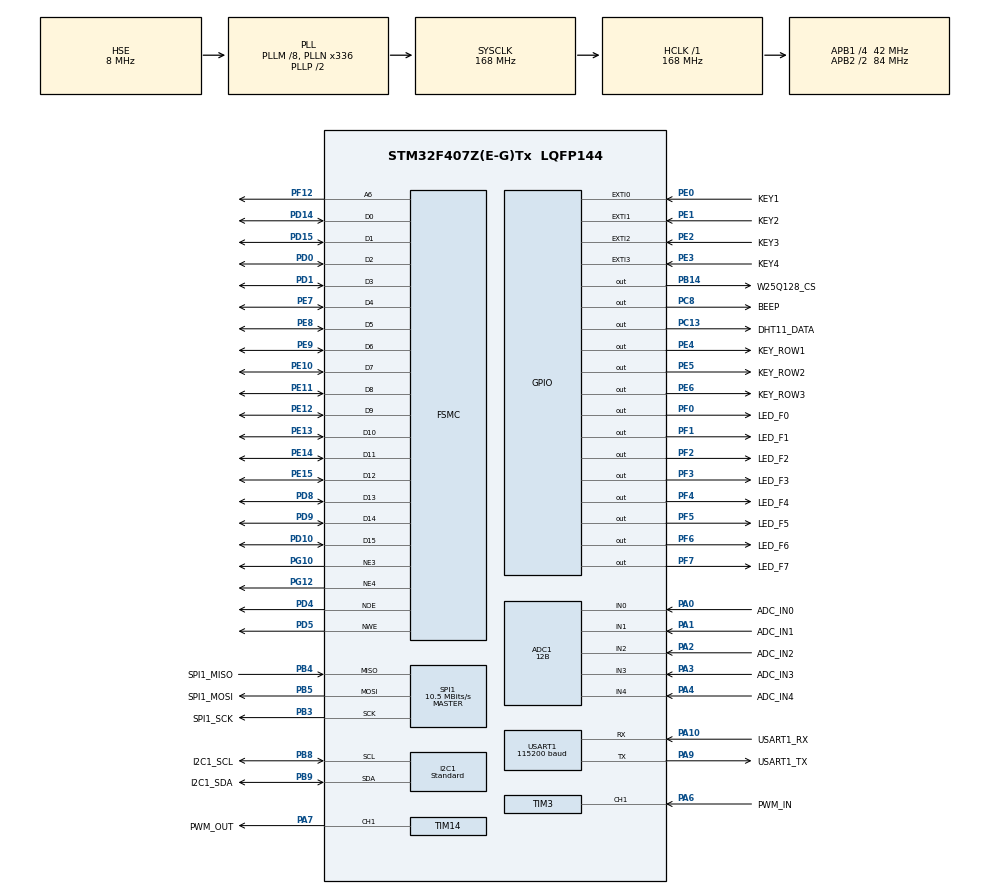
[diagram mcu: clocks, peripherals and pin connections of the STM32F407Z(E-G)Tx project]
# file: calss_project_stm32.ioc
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ADC1.Channel-0\#ChannelRegularConversion=ADC_CHANNEL_0
ADC1.Channel-1\#ChannelRegularConversion=ADC_CHANNEL_1
ADC1.Channel-2\#ChannelRegularConversion=ADC_CHANNEL_2
ADC1.Channel-3\#ChannelRegularConversion=ADC_CHANNEL_3
ADC1.Channel-4\#ChannelRegularConversion=ADC_CHANNEL_4
ADC1.ContinuousConvMode=ENABLE
ADC1.DMAContinuousRequests=ENABLE
ADC1.DataAlign=ADC_DATAALIGN_RIGHT
ADC1.DiscontinuousConvMode=DISABLE
ADC1.EOCSelection=ADC_EOC_SINGLE_CONV
ADC1.ExternalTrigConv=ADC_SOFTWARE_START
ADC1.ExternalTrigConvEdge=ADC_EXTERNALTRIGCONVEDGE_NONE
ADC1.NbrOfConversion=5
ADC1.NbrOfConversionFlag=1
ADC1.Overrun=ADC_OVR_DATA_PRESERVED
ADC1.Rank-0\#ChannelRegularConversion=1
ADC1.Rank-1\#ChannelRegularConversion=2
ADC1.Rank-2\#ChannelRegularConversion=3
ADC1.Rank-3\#ChannelRegularConversion=4
ADC1.Rank-4\#ChannelRegularConversion=5
ADC1.Resolution=ADC_RESOLUTION_12B
ADC1.SamplingTime-0\#ChannelRegularConversion=ADC_SAMPLETIME_84CYCLES
ADC1.SamplingTime-1\#ChannelRegularConversion=ADC_SAMPLETIME_84CYCLES
ADC1.SamplingTime-2\#ChannelRegularConversion=ADC_SAMPLETIME_84CYCLES
ADC1.SamplingTime-3\#ChannelRegularConversion=ADC_SAMPLETIME_84CYCLES
ADC1.SamplingTime-4\#ChannelRegularConversion=ADC_SAMPLETIME_84CYCLES
ADC1.ScanConvMode=ENABLE
ADC1.master=1
Dma.ADC1.0.Direction=DMA_PERIPH_TO_MEMORY
Dma.ADC1.0.FIFOMode=DMA_FIFOMODE_DISABLE
Dma.ADC1.0.Instance=DMA2_Stream0
Dma.ADC1.0.MemDataAlignment=DMA_MDATAALIGN_HALFWORD
Dma.ADC1.0.MemInc=DMA_MINC_ENABLE
Dma.ADC1.0.Mode=DMA_CIRCULAR
Dma.ADC1.0.PeriphDataAlignment=DMA_PDATAALIGN_HALFWORD
Dma.ADC1.0.PeriphInc=DMA_PINC_DISABLE
Dma.ADC1.0.Priority=DMA_PRIORITY_MEDIUM
Dma.Request0=ADC1
FREERTOS.Tasks01=myTask_key,24,128,StartTask_key,Default,NULL,Dynamic,NULL,NULL;myTask_control,16,256,StartTask_control,Default,NULL,Dynamic,NULL,NULL;myTask_shell,24,512,StartTask_shell,Default,NULL,Dynamic,NULL,NULL;myTask_timer,24,256,StartTask_timer,Default,NULL,Dynamic,NULL,NULL;myTask_seg,16,128,StartTask_seg,Default,NULL,Dynamic,NULL,NULL;myTask_lcd,16,512,StartTask_lcd,Default,NULL,Dynamic,NULL,NULL
I2C1.I2C_Speed_Mode=I2C_Standard
I2C1.Speed=100
Mcu.Family=STM32F4
Mcu.Name=STM32F407Z(E-G)Tx
Mcu.Package=LQFP144
NVIC.DMA2_Stream0_IRQn=true\:5\:0\:false\:false\:true\:true\:true\:true\:true
NVIC.EXTI0_IRQn=true\:5\:0\:false\:false\:true\:true\:true\:true\:true
NVIC.EXTI1_IRQn=true\:5\:0\:false\:false\:true\:true\:true\:true\:true
NVIC.EXTI2_IRQn=true\:5\:0\:false\:false\:true\:true\:true\:true\:true
NVIC.EXTI3_IRQn=true\:5\:0\:false\:false\:true\:true\:true\:true\:true
NVIC.PriorityGroup=NVIC_PRIORITYGROUP_4
NVIC.TIM1_UP_TIM10_IRQn=true\:15\:0\:false\:false\:true\:false\:false\:true\:true
NVIC.TIM3_IRQn=true\:5\:0\:false\:false\:true\:true\:true\:true\:true
NVIC.TIM6_DAC_IRQn=true\:5\:0\:false\:false\:true\:true\:true\:true\:true
NVIC.TimeBase=TIM1_UP_TIM10_IRQn
NVIC.TimeBaseIP=TIM1
NVIC.USART1_IRQn=true\:5\:0\:false\:false\:true\:true\:true\:true\:true
PA0-WKUP.GPIO_Label=ADC_IN0
PA0-WKUP.Signal=ADCx_IN0
PA1.GPIO_Label=ADC_IN1
PA1.Signal=ADCx_IN1
PA10.GPIO_Label=USART1_RX
PA10.GPIO_Mode=GPIO_MODE_AF_PP
PA10.GPIO_PuPd=GPIO_NOPULL
PA10.GPIO_Speed=GPIO_SPEED_FREQ_VERY_HIGH
PA10.Mode=Asynchronous
PA10.Signal=USART1_RX
PA13.Mode=Serial_Wire
PA13.Signal=SYS_JTMS-SWDIO
PA14.Mode=Serial_Wire
PA14.Signal=SYS_JTCK-SWCLK
PA2.GPIO_Label=ADC_IN2
PA2.Signal=ADCx_IN2
PA3.GPIO_Label=ADC_IN3
PA3.Signal=ADCx_IN3
PA4.GPIO_Label=ADC_IN4
PA4.Signal=ADCx_IN4
PA6.GPIO_Label=PWM_IN
PA6.Signal=S_TIM3_CH1
PA7.GPIO_Label=PWM_OUT
PA7.Signal=S_TIM14_CH1
PA9.GPIO_Label=USART1_TX
PA9.GPIO_Mode=GPIO_MODE_AF_PP
PA9.GPIO_PuPd=GPIO_NOPULL
PA9.GPIO_Speed=GPIO_SPEED_FREQ_VERY_HIGH
PA9.Mode=Asynchronous
PA9.Signal=USART1_TX
PB14.GPIO_Label=W25Q128_CS
PB14.GPIO_Speed=GPIO_SPEED_FREQ_HIGH
PB14.PinState=GPIO_PIN_SET
PB14.Signal=GPIO_Output
PB3.GPIO_Label=SPI1_SCK
PB3.GPIO_Mode=GPIO_MODE_AF_PP
PB3.GPIO_PuPd=GPIO_NOPULL
PB3.GPIO_Speed=GPIO_SPEED_FREQ_VERY_HIGH
PB3.Mode=Full_Duplex_Master
PB3.Signal=SPI1_SCK
PB4.GPIO_Label=SPI1_MISO
PB4.GPIO_Mode=GPIO_MODE_AF_PP
PB4.GPIO_PuPd=GPIO_NOPULL
PB4.GPIO_Speed=GPIO_SPEED_FREQ_VERY_HIGH
PB4.Mode=Full_Duplex_Master
PB4.Signal=SPI1_MISO
PB5.GPIO_Label=SPI1_MOSI
PB5.GPIO_Mode=GPIO_MODE_AF_PP
PB5.GPIO_PuPd=GPIO_NOPULL
PB5.GPIO_Speed=GPIO_SPEED_FREQ_VERY_HIGH
PB5.Mode=Full_Duplex_Master
PB5.Signal=SPI1_MOSI
PB8.GPIO_Label=I2C1_SCL
PB8.GPIO_Mode=GPIO_MODE_AF_OD
PB8.GPIO_PuPd=GPIO_NOPULL
PB8.GPIO_Speed=GPIO_SPEED_FREQ_LOW
PB8.Mode=I2C
PB8.Signal=I2C1_SCL
PB9.GPIO_Label=I2C1_SDA
PB9.GPIO_Mode=GPIO_MODE_AF_OD
PB9.GPIO_PuPd=GPIO_NOPULL
PB9.GPIO_Speed=GPIO_SPEED_FREQ_LOW
PB9.Mode=I2C
PB9.Signal=I2C1_SDA
PC13-ANTI_TAMP.GPIO_Label=DHT11_DATA
PC13-ANTI_TAMP.GPIO_ModeDefaultOutputPP=GPIO_MODE_OUTPUT_OD
PC13-ANTI_TAMP.GPIO_Speed=GPIO_SPEED_FREQ_LOW
PC13-ANTI_TAMP.PinState=GPIO_PIN_SET
PC13-ANTI_TAMP.Signal=GPIO_Output
PC8.GPIO_Label=BEEP
PC8.GPIO_Speed=GPIO_SPEED_FREQ_LOW
PC8.PinState=GPIO_PIN_SET
PC8.Signal=GPIO_Output
PD0.Signal=FSMC_D2_DA2
PD1.Signal=FSMC_D3_DA3
PD10.Signal=FSMC_D15_DA15
PD14.Signal=FSMC_D0_DA0
PD15.Signal=FSMC_D1_DA1
PD4.Signal=FSMC_NOE
PD5.Signal=FSMC_NWE
PD8.Signal=FSMC_D13_DA13
PD9.Signal=FSMC_D14_DA14
PE0.GPIO_Label=KEY1
PE0.GPIO_ModeDefaultEXTI=GPIO_MODE_IT_FALLING
PE0.GPIO_PuPd=GPIO_PULLUP
PE0.Signal=GPXTI0
PE1.GPIO_Label=KEY2
PE1.GPIO_ModeDefaultEXTI=GPIO_MODE_IT_FALLING
PE1.GPIO_PuPd=GPIO_PULLUP
PE1.Signal=GPXTI1
PE10.Signal=FSMC_D7_DA7
PE11.Signal=FSMC_D8_DA8
PE12.Signal=FSMC_D9_DA9
PE13.Signal=FSMC_D10_DA10
PE14.Signal=FSMC_D11_DA11
PE15.Signal=FSMC_D12_DA12
PE2.GPIO_Label=KEY3
PE2.GPIO_ModeDefaultEXTI=GPIO_MODE_IT_FALLING
PE2.GPIO_PuPd=GPIO_PULLUP
PE2.Signal=GPXTI2
PE3.GPIO_Label=KEY4
PE3.GPIO_ModeDefaultEXTI=GPIO_MODE_IT_FALLING
PE3.GPIO_PuPd=GPIO_PULLUP
PE3.Signal=GPXTI3
PE4.GPIO_Label=KEY_ROW1
PE4.GPIO_Speed=GPIO_SPEED_FREQ_LOW
PE4.PinState=GPIO_PIN_SET
PE4.Signal=GPIO_Output
PE5.GPIO_Label=KEY_ROW2
PE5.GPIO_Speed=GPIO_SPEED_FREQ_LOW
PE5.PinState=GPIO_PIN_SET
PE5.Signal=GPIO_Output
PE6.GPIO_Label=KEY_ROW3
PE6.GPIO_Speed=GPIO_SPEED_FREQ_LOW
PE6.PinState=GPIO_PIN_SET
PE6.Signal=GPIO_Output
PE7.Signal=FSMC_D4_DA4
PE8.Signal=FSMC_D5_DA5
PE9.Signal=FSMC_D6_DA6
PF0.GPIO_Label=LED_F0
PF0.GPIO_Speed=GPIO_SPEED_FREQ_LOW
PF0.PinState=GPIO_PIN_SET
PF0.Signal=GPIO_Output
PF1.GPIO_Label=LED_F1
PF1.GPIO_Speed=GPIO_SPEED_FREQ_LOW
PF1.PinState=GPIO_PIN_SET
PF1.Signal=GPIO_Output
PF12.Signal=FSMC_A6
PF2.GPIO_Label=LED_F2
PF2.GPIO_Speed=GPIO_SPEED_FREQ_LOW
PF2.PinState=GPIO_PIN_SET
PF2.Signal=GPIO_Output
PF3.GPIO_Label=LED_F3
PF3.GPIO_Speed=GPIO_SPEED_FREQ_LOW
PF3.PinState=GPIO_PIN_SET
PF3.Signal=GPIO_Output
PF4.GPIO_Label=LED_F4
PF4.GPIO_Speed=GPIO_SPEED_FREQ_LOW
PF4.PinState=GPIO_PIN_SET
PF4.Signal=GPIO_Output
PF5.GPIO_Label=LED_F5
PF5.GPIO_Speed=GPIO_SPEED_FREQ_LOW
PF5.PinState=GPIO_PIN_SET
PF5.Signal=GPIO_Output
PF6.GPIO_Label=LED_F6
PF6.GPIO_Speed=GPIO_SPEED_FREQ_LOW
PF6.PinState=GPIO_PIN_SET
PF6.Signal=GPIO_Output
PF7.GPIO_Label=LED_F7
PF7.GPIO_Speed=GPIO_SPEED_FREQ_LOW
PF7.PinState=GPIO_PIN_SET
PF7.Signal=GPIO_Output
PG10.Mode=NorPsramChipSelect3_3
PG10.Signal=FSMC_NE3
PG12.Mode=NorPsramChipSelect4_4
PG12.Signal=FSMC_NE4
PH0-OSC_IN.GPIO_Label=PH0-OSC_IN
PH0-OSC_IN.Mode=HSE-External-Oscillator
PH0-OSC_IN.Signal=RCC_OSC_IN
PH1-OSC_OUT.GPIO_Label=PH1-OSC_OUT
PH1-OSC_OUT.Mode=HSE-External-Oscillator
PH1-OSC_OUT.Signal=RCC_OSC_OUT
ProjectManager.HeapSize=0x200
ProjectManager.StackSize=0x400
ProjectManager.TargetToolchain=MDK-ARM V5.32
RCC.48MHZClocksFreq_Value=48000000
RCC.AHBFreq_Value=168000000
RCC.APB1CLKDivider=RCC_HCLK_DIV4
RCC.APB1Freq_Value=42000000
RCC.APB1TimFreq_Value=84000000
RCC.APB2CLKDivider=RCC_HCLK_DIV2
RCC.APB2Freq_Value=84000000
RCC.APB2TimFreq_Value=168000000
RCC.CortexFreq_Value=168000000
RCC.HCLKFreq_Value=168000000
RCC.HSE_VALUE=8000000
RCC.HSI_VALUE=16000000
RCC.LSE_VALUE=32768
RCC.OscillatorType=RCC_OSCILLATORTYPE_HSE|RCC_OSCILLATORTYPE_LSI
RCC.PLLM=8
RCC.PLLN=336
RCC.PLLQ=7
RCC.PLLSourceVirtual=RCC_PLLSOURCE_HSE
RCC.SYSCLKFreq_VALUE=168000000
RCC.SYSCLKSource=RCC_SYSCLKSOURCE_PLLCLK
RCC.VCOOutputFreq_Value=336000000
RTC.Alarm=RTC_ALARM_A
SH.ADCx_IN0.0=ADC1_IN0,IN0
SH.ADCx_IN1.0=ADC1_IN1,IN1
SH.ADCx_IN2.0=ADC1_IN2,IN2
SH.ADCx_IN3.0=ADC1_IN3,IN3
SH.ADCx_IN4.0=ADC1_IN4,IN4
SH.FSMC_A6.0=FSMC_A6,A6_3
SH.FSMC_A6.1=FSMC_A6,A6_4
SH.FSMC_D0_DA0.0=FSMC_D0,16b-d3
SH.FSMC_D0_DA0.1=FSMC_D0,16b-d4
SH.FSMC_D10_DA10.0=FSMC_D10,16b-d3
SH.FSMC_D10_DA10.1=FSMC_D10,16b-d4
SH.FSMC_D11_DA11.0=FSMC_D11,16b-d3
SH.FSMC_D11_DA11.1=FSMC_D11,16b-d4
SH.FSMC_D12_DA12.0=FSMC_D12,16b-d3
SH.FSMC_D12_DA12.1=FSMC_D12,16b-d4
SH.FSMC_D13_DA13.0=FSMC_D13,16b-d3
SH.FSMC_D13_DA13.1=FSMC_D13,16b-d4
SH.FSMC_D14_DA14.0=FSMC_D14,16b-d3
SH.FSMC_D14_DA14.1=FSMC_D14,16b-d4
SH.FSMC_D15_DA15.0=FSMC_D15,16b-d3
SH.FSMC_D15_DA15.1=FSMC_D15,16b-d4
SH.FSMC_D1_DA1.0=FSMC_D1,16b-d3
SH.FSMC_D1_DA1.1=FSMC_D1,16b-d4
SH.FSMC_D2_DA2.0=FSMC_D2,16b-d3
SH.FSMC_D2_DA2.1=FSMC_D2,16b-d4
SH.FSMC_D3_DA3.0=FSMC_D3,16b-d3
SH.FSMC_D3_DA3.1=FSMC_D3,16b-d4
SH.FSMC_D4_DA4.0=FSMC_D4,16b-d3
SH.FSMC_D4_DA4.1=FSMC_D4,16b-d4
SH.FSMC_D5_DA5.0=FSMC_D5,16b-d3
SH.FSMC_D5_DA5.1=FSMC_D5,16b-d4
SH.FSMC_D6_DA6.0=FSMC_D6,16b-d3
SH.FSMC_D6_DA6.1=FSMC_D6,16b-d4
SH.FSMC_D7_DA7.0=FSMC_D7,16b-d3
SH.FSMC_D7_DA7.1=FSMC_D7,16b-d4
SH.FSMC_D8_DA8.0=FSMC_D8,16b-d3
SH.FSMC_D8_DA8.1=FSMC_D8,16b-d4
SH.FSMC_D9_DA9.0=FSMC_D9,16b-d3
SH.FSMC_D9_DA9.1=FSMC_D9,16b-d4
SH.FSMC_NOE.0=FSMC_NOE,Lcd3
SH.FSMC_NOE.1=FSMC_NOE,Lcd4
SH.FSMC_NWE.0=FSMC_NWE,Lcd3
SH.FSMC_NWE.1=FSMC_NWE,Lcd4
SH.S_TIM14_CH1.0=TIM14_CH1,PWM Generation1 CH1
SH.S_TIM3_CH1.0=TIM3_CH1,PWM_Input_1
SPI1.BaudRatePrescaler=SPI_BAUDRATEPRESCALER_8
SPI1.CLKPhase=SPI_PHASE_2EDGE
SPI1.CLKPolarity=SPI_POLARITY_HIGH
SPI1.CalculateBaudRate=10.5 MBits/s
SPI1.DataSize=SPI_DATASIZE_8BIT
SPI1.Direction=SPI_DIRECTION_2LINES
SPI1.FirstBit=SPI_FIRSTBIT_MSB
SPI1.Mode=SPI_MODE_MASTER
SPI1.NSS=SPI_NSS_SOFT
SPI1.VirtualType=VM_MASTER
TIM14.Channel=TIM_CHANNEL_1
TIM14.Period=999
TIM14.Prescaler=83
TIM3.Channel-PWM_Input_1=TIM_CHANNEL_1
TIM3.Period=65535
TIM3.Prescaler=83
TIM6.Period=9999
TIM6.Prescaler=8399
USART1.BaudRate=115200
USART1.VirtualMode=VM_ASYNC
VP_FREERTOS_VS_CMSIS_V2.Mode=CMSIS_V2
VP_RTC_VS_RTC_Activate.Mode=RTC_Enabled
VP_RTC_VS_RTC_Alarm_A_Intern.Mode=Alarm A
VP_RTC_VS_RTC_Calendar.Mode=RTC_Calendar
VP_SYS_VS_tim1.Mode=TIM1
VP_TIM14_VS_ClockSourceINT.Mode=Enable_Timer
VP_TIM6_VS_ClockSourceINT.Mode=Enable_Timer
board=custom

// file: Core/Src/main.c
/* USER CODE BEGIN Header */
/**
  ******************************************************************************
  * @file           : main.c
  * @brief          : Main program body
  ******************************************************************************
  * @attention
  *
  * Copyright (c) 2026 STMicroelectronics.
  * All rights reserved.
  *
  * This software is licensed under terms that can be found in the LICENSE file
  * in the root directory of this software component.
  * If no LICENSE file comes with this software, it is provided AS-IS.
  *
  ******************************************************************************
  */
/* USER CODE END Header */
#include "main.h"
#include "cmsis_os.h"
#include "adc.h"
#include "dma.h"
#include "i2c.h"
#include "rtc.h"
#include "spi.h"
#include "tim.h"
#include "usart.h"
#include "gpio.h"
#include "fsmc.h"

/* USER CODE BEGIN Includes */
#include "my_main.h"
#include "config.h"
/* USER CODE END Includes */

void SystemClock_Config(void);
void MX_FREERTOS_Init(void);

int main(void)
{

  /* MCU Configuration--------------------------------------------------------*/

  /* Reset of all peripherals, Initializes the Flash interface and the Systick. */
  HAL_Init();

  /* Configure the system clock */
  SystemClock_Config();

  /* Initialize all configured peripherals */
  MX_GPIO_Init();
  MX_DMA_Init();
  MX_ADC1_Init();
  MX_I2C1_Init();
  MX_SPI1_Init();
  MX_USART1_UART_Init();
  MX_TIM3_Init();
  MX_TIM14_Init();
  MX_TIM6_Init();
  MX_FSMC_Init();
  MX_RTC_Init();
  /* USER CODE BEGIN 2 */
  my_main();
  /* USER CODE END 2 */

  /* Init scheduler */
  osKernelInitialize();  /* Call init function for freertos objects (in cmsis_os2.c) */
  MX_FREERTOS_Init();

  /* Start scheduler */
  osKernelStart();

  /* We should never get here as control is now taken by the scheduler */

  /* Infinite loop */
  while (1)
  {

  }
}

void SystemClock_Config(void)
{
  RCC_OscInitTypeDef RCC_OscInitStruct = {0};
  RCC_ClkInitTypeDef RCC_ClkInitStruct = {0};

  /** Configure the main internal regulator output voltage
  */
  __HAL_RCC_PWR_CLK_ENABLE();
  __HAL_PWR_VOLTAGESCALING_CONFIG(PWR_REGULATOR_VOLTAGE_SCALE1);

  /** Initializes the RCC Oscillators according to the specified parameters
  * in the RCC_OscInitTypeDef structure.
  */
  RCC_OscInitStruct.OscillatorType = RCC_OSCILLATORTYPE_HSE|RCC_OSCILLATORTYPE_LSI;
  RCC_OscInitStruct.HSEState = RCC_HSE_ON;
  RCC_OscInitStruct.LSIState = RCC_LSI_ON;
  RCC_OscInitStruct.PLL.PLLState = RCC_PLL_ON;
  RCC_OscInitStruct.PLL.PLLSource = RCC_PLLSOURCE_HSE;
  RCC_OscInitStruct.PLL.PLLM = 8;
  RCC_OscInitStruct.PLL.PLLN = 336;
  RCC_OscInitStruct.PLL.PLLP = RCC_PLLP_DIV2;
  RCC_OscInitStruct.PLL.PLLQ = 7;
  if (HAL_RCC_OscConfig(&RCC_OscInitStruct) != HAL_OK)
  {
    Error_Handler();
  }

  /** Initializes the CPU, AHB and APB buses clocks
  */
  RCC_ClkInitStruct.ClockType = RCC_CLOCKTYPE_HCLK|RCC_CLOCKTYPE_SYSCLK
                              |RCC_CLOCKTYPE_PCLK1|RCC_CLOCKTYPE_PCLK2;
  RCC_ClkInitStruct.SYSCLKSource = RCC_SYSCLKSOURCE_PLLCLK;
  RCC_ClkInitStruct.AHBCLKDivider = RCC_SYSCLK_DIV1;
  RCC_ClkInitStruct.APB1CLKDivider = RCC_HCLK_DIV4;
  RCC_ClkInitStruct.APB2CLKDivider = RCC_HCLK_DIV2;

  if (HAL_RCC_ClockConfig(&RCC_ClkInitStruct, FLASH_LATENCY_5) != HAL_OK)
  {
    Error_Handler();
  }
}

void HAL_TIM_PeriodElapsedCallback(TIM_HandleTypeDef *htim)
{
  if (htim->Instance == TIM1)
  {
    HAL_IncTick();
  }
  /* USER CODE BEGIN Callback 1 */
#if CFG_TIM6_EN
  if (htim->Instance == TIM6)
  {
    app_timer_irq_handler();
  }
#endif
  /* USER CODE END Callback 1 */
}

void Error_Handler(void)
{
  __disable_irq();
  while (1)
  {
  }
}

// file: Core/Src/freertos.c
/* USER CODE BEGIN Header */
/**
  ******************************************************************************
  * File Name          : freertos.c
  * Description        : Code for freertos applications
  ******************************************************************************
  * @attention
  *
  * Copyright (c) 2026 STMicroelectronics.
  * All rights reserved.
  *
  * This software is licensed under terms that can be found in the LICENSE file
  * in the root directory of this software component.
  * If no LICENSE file comes with this software, it is provided AS-IS.
  *
  ******************************************************************************
  */
/* USER CODE END Header */

#include "FreeRTOS.h"
#include "task.h"
#include "main.h"
#include "cmsis_os.h"

/* USER CODE BEGIN Includes */
#include "my_main.h"
/* USER CODE END Includes */

/* Definitions for myTask_key */
osThreadId_t myTask_keyHandle;
const osThreadAttr_t myTask_key_attributes = {
  .name = "myTask_key",
  .stack_size = 128 * 4,
  .priority = (osPriority_t) osPriorityNormal,
};
/* Definitions for myTask_control */
osThreadId_t myTask_controlHandle;
const osThreadAttr_t myTask_control_attributes = {
  .name = "myTask_control",
  .stack_size = 256 * 4,
  .priority = (osPriority_t) osPriorityBelowNormal,
};
/* Definitions for myTask_shell */
osThreadId_t myTask_shellHandle;
const osThreadAttr_t myTask_shell_attributes = {
  .name = "myTask_shell",
  .stack_size = 512 * 4,
  .priority = (osPriority_t) osPriorityNormal,
};
/* Definitions for myTask_timer */
osThreadId_t myTask_timerHandle;
const osThreadAttr_t myTask_timer_attributes = {
  .name = "myTask_timer",
  .stack_size = 256 * 4,
  .priority = (osPriority_t) osPriorityNormal,
};
/* Definitions for myTask_seg */
osThreadId_t myTask_segHandle;
const osThreadAttr_t myTask_seg_attributes = {
  .name = "myTask_seg",
  .stack_size = 128 * 4,
  .priority = (osPriority_t) osPriorityBelowNormal,
};
/* Definitions for myTask_lcd */
osThreadId_t myTask_lcdHandle;
const osThreadAttr_t myTask_lcd_attributes = {
  .name = "myTask_lcd",
  .stack_size = 512 * 4,
  .priority = (osPriority_t) osPriorityBelowNormal,
};

void StartTask_key(void *argument);
void StartTask_control(void *argument);
void StartTask_shell(void *argument);
void StartTask_timer(void *argument);
void StartTask_seg(void *argument);
void StartTask_lcd(void *argument);

void MX_FREERTOS_Init(void); /* (MISRA C 2004 rule 8.1) */

void MX_FREERTOS_Init(void) {

  /* Create the thread(s) */
  /* creation of myTask_key */
  myTask_keyHandle = osThreadNew(StartTask_key, NULL, &myTask_key_attributes);

  /* creation of myTask_control */
  myTask_controlHandle = osThreadNew(StartTask_control, NULL, &myTask_control_attributes);

  /* creation of myTask_shell */
  myTask_shellHandle = osThreadNew(StartTask_shell, NULL, &myTask_shell_attributes);

  /* creation of myTask_timer */
  myTask_timerHandle = osThreadNew(StartTask_timer, NULL, &myTask_timer_attributes);

  /* creation of myTask_seg */
  myTask_segHandle = osThreadNew(StartTask_seg, NULL, &myTask_seg_attributes);

  /* creation of myTask_lcd */
  myTask_lcdHandle = osThreadNew(StartTask_lcd, NULL, &myTask_lcd_attributes);

}

void StartTask_key(void *argument)
{
  /* USER CODE BEGIN StartTask_key */
  app_task_key(argument);
  /* USER CODE END StartTask_key */
}

void StartTask_control(void *argument)
{
  /* USER CODE BEGIN StartTask_control */
  app_task_control(argument);
  /* USER CODE END StartTask_control */
}

void StartTask_shell(void *argument)
{
  /* USER CODE BEGIN StartTask_shell */
  app_task_shell(argument);
  /* USER CODE END StartTask_shell */
}

void StartTask_timer(void *argument)
{
  /* USER CODE BEGIN StartTask_timer */
  app_task_timer(argument);
  /* USER CODE END StartTask_timer */
}

void StartTask_seg(void *argument)
{
  /* USER CODE BEGIN StartTask_seg */
  app_task_seg(argument);
  /* USER CODE END StartTask_seg */
}

void StartTask_lcd(void *argument)
{
  /* USER CODE BEGIN StartTask_lcd */
  app_task_lcd(argument);
  /* USER CODE END StartTask_lcd */
}
